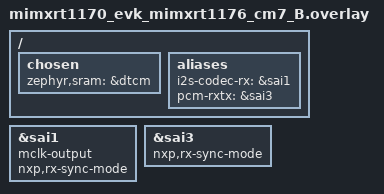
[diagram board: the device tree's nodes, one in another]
/*
 * Copyright 2024-2025 NXP
 *
 * SPDX-License-Identifier: Apache-2.0
 */

/ {
	chosen {
		zephyr,sram = &dtcm;
	};

	aliases {
		i2s-codec-rx = &sai1;
		pcm-rxtx = &sai3;
	};
};

&sai1 {
	status = "okay";
	mclk-output;
	nxp,rx-sync-mode;
};

&sai3 {
	status = "okay";
	nxp,rx-sync-mode;
};
